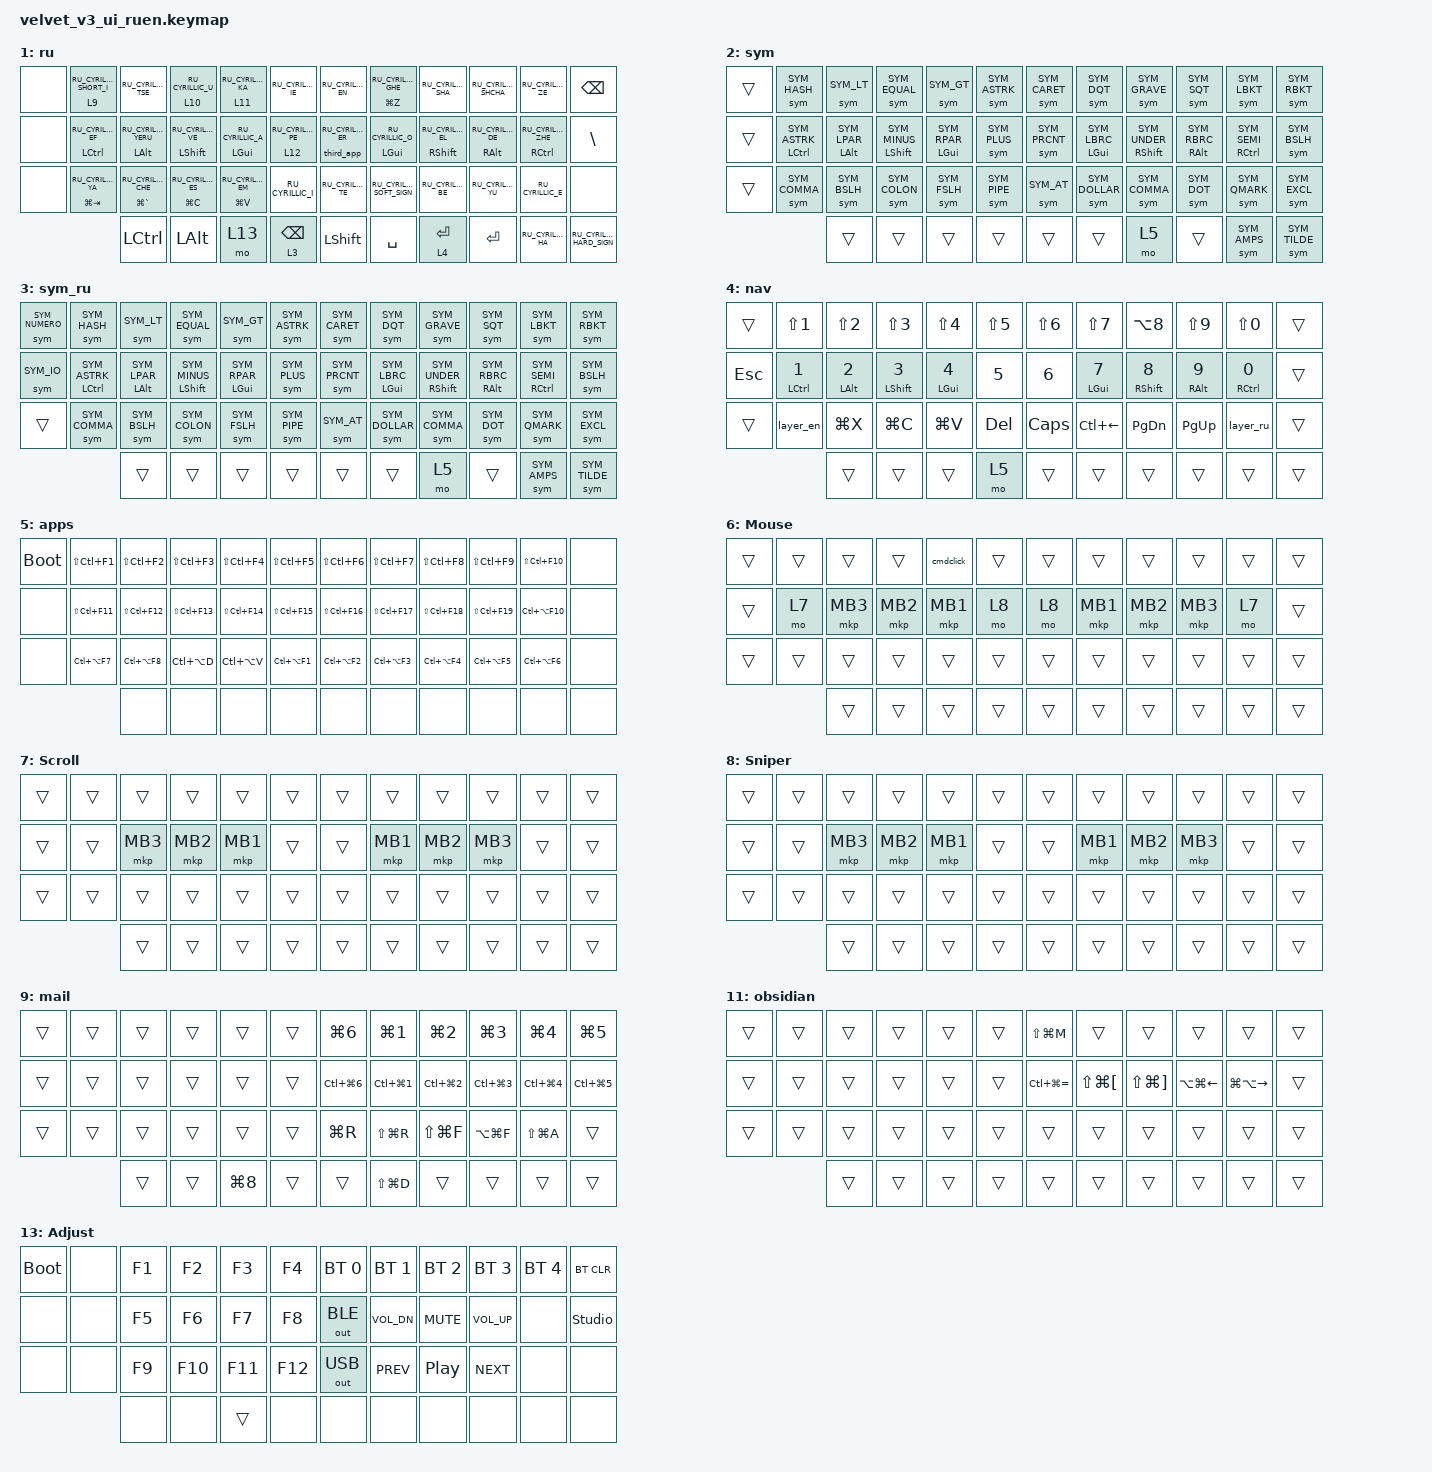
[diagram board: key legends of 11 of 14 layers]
#include "keys_ru.h"
#include "host_layout.dtsi"
#include "sym_glyph.h"
#include "sym_glyph.dtsi"
#include <dt-bindings/zmk/input_transform.h>
#include <input/processors.dtsi>
#include <zephyr/dt-bindings/input/input-event-codes.h>
#include <behaviors.dtsi>
#include <dt-bindings/zmk/bt.h>
#include <dt-bindings/zmk/keys.h>
#include <dt-bindings/zmk/outputs.h>
#include <dt-bindings/zmk/pointing.h>

&mt {
    quick-tap-ms = <175>;
    require-prior-idle-ms = <150>;
    flavor = "tap-preferred";
};

&lt {
    quick-tap-ms = <175>;
    require-prior-idle-ms = <150>;
    hold-while-undecided;
};

/ {
    behaviors {
        cap_sen: cap_sen {
            compatible = "zmk,behavior-hold-tap";
            label = "CAP_SEN";
            bindings = <&mo>, <&mkp>;

            #binding-cells = <2>;
            tapping-term-ms = <150>;
            hold-while-undecided;
        };

        mouse_layer: mouse_layer {
            compatible = "zmk,behavior-sticky-key";
            label = "MOUSE_LAYER";
            bindings = <&mo>;
            #binding-cells = <1>;
            release-after-ms = <200>;
        };

        /* Time-based home-row mods, same idea as toucan hrm_l / hrm_r:
         * the key becomes a modifier only after it has been held for
         * tapping-term-ms. quick-tap-ms matches that term, so a repeated
         * letter stays a tap.
         */
        hml: home_row_mod_left {
            compatible = "zmk,behavior-hold-tap";
            #binding-cells = <2>;
            bindings = <&kp>, <&kp>;
            flavor = "tap-preferred";
            tapping-term-ms = <300>;
            quick-tap-ms = <300>;
        };

        hmr: home_row_mod_right {
            compatible = "zmk,behavior-hold-tap";
            #binding-cells = <2>;
            bindings = <&kp>, <&kp>;
            flavor = "tap-preferred";
            tapping-term-ms = <300>;
            quick-tap-ms = <300>;
        };

        /* Symbol-layer home row: hold is still a modifier, tap is &sym. */
        hml_sym: home_row_mod_left_sym {
            compatible = "zmk,behavior-hold-tap";
            #binding-cells = <2>;
            bindings = <&kp>, <&sym>;
            flavor = "tap-preferred";
            tapping-term-ms = <300>;
            quick-tap-ms = <300>;
        };

        hmr_sym: home_row_mod_right_sym {
            compatible = "zmk,behavior-hold-tap";
            #binding-cells = <2>;
            bindings = <&kp>, <&sym>;
            flavor = "tap-preferred";
            tapping-term-ms = <300>;
            quick-tap-ms = <300>;
        };

        my_mt: my_mt {
            compatible = "zmk,behavior-hold-tap";
            bindings = <&kp>, <&kp>;

            #binding-cells = <2>;
            tapping-term-ms = <300>;
        };

        /* W+E combo: tap sends Tab, hold sends Enter. Same timing as toucan my_mt. */
        mt_tab: mt_tab {
            compatible = "zmk,behavior-hold-tap";
            #binding-cells = <2>;
            flavor = "tap-preferred";
            tapping-term-ms = <300>;
            bindings = <&kp>, <&kp>;
        };

        /* Hold H: Cmd+Tab+Tab, the third recent app. Tap still sends the letter. */
        h_third_app: h_third_app {
            compatible = "zmk,behavior-hold-tap";
            #binding-cells = <2>;
            flavor = "tap-preferred";
            tapping-term-ms = <300>;
            bindings = <&third_app>, <&kp>;
        };

        /* Hold: layer 12 (same as `&lt 12`). Tap: `&to` — same as layer_en (0) / layer_ru (1). */
        lt12_to: lt12_to {
            compatible = "zmk,behavior-hold-tap";
            #binding-cells = <2>;
            bindings = <&mo>, <&to>;
            tapping-term-ms = <200>;
            quick-tap-ms = <175>;
            require-prior-idle-ms = <150>;
            hold-while-undecided;
        };

        zip_auto_mouse: zip_auto_mouse {
            compatible = "zmk,input-processor-temp-layer";
            #input-processor-cells = <2>;
            require-prior-idle-ms = <800>;
            excluded-positions = <>;
        };

        /* E+R. Horizon: Alt+Shift for Windows. Otherwise toggle en/ru. */
        er_lang: er_lang {
            compatible = "zmk,behavior-er-lang";
            #binding-cells = <0>;
            display-name = "ER Lang";
        };
    };

    combos {
        compatible = "zmk,combos";

        er {
            bindings = <&er_lang>;
            key-positions = <3 4>;
            layers = <0 1>;
        };

        kha {
            bindings = <&kp RU_CYRILLIC_HA>;
            key-positions = <7 8>;
            layers = <1>;
        };

        hrd {
            bindings = <&kp RU_CYRILLIC_HARD_SIGN>;
            key-positions = <8 9>;
            layers = <1>;
        };

        caps_word {
            bindings = <&caps_word>;
            key-positions = <24 25>;
            layers = <0 1>;
        };

        combo_sd_esc {
            timeout-ms = <35>;
            require-prior-idle-ms = <125>;
            slow-release;
            key-positions = <14 15>;
            layers = <0 1>;
            bindings = <&kp ESC>;
        };

        combo_we_tab {
            timeout-ms = <35>;
            require-prior-idle-ms = <125>;
            slow-release;
            key-positions = <2 3>;
            layers = <0 1>;
            bindings = <&mt_tab RET TAB>;
        };
    };

    macros {
        to_ru: to_ru {
            compatible = "zmk,behavior-macro";
            #binding-cells = <0>;
            bindings = <&host_layout 1>;
            label = "TO_RU";
            wait-ms = <0>;
            tap-ms = <30>;
        };

        to_en: to_en {
            compatible = "zmk,behavior-macro";
            #binding-cells = <0>;
            bindings = <&host_layout 0>;
            label = "TO_EN";
            wait-ms = <0>;
            tap-ms = <30>;
        };

        layer_en: layer_en {
            compatible = "zmk,behavior-macro";
            #binding-cells = <0>;
            bindings = <&to 0>;
            label = "LAYER_EN";
            wait-ms = <0>;
            tap-ms = <30>;
        };

        layer_ru: layer_ru {
            compatible = "zmk,behavior-macro";
            #binding-cells = <0>;
            bindings = <&to 1>;
            label = "LAYER_RU";
            tap-ms = <30>;
            wait-ms = <0>;
        };

        en: en {
            compatible = "zmk,behavior-macro-one-param";
            #binding-cells = <1>;
            bindings =
                <&to_en>,
                <&macro_press>,
                <&macro_param_1to1 &host_key MACRO_PLACEHOLDER>,
                <&macro_pause_for_release>,
                <&macro_release>,
                <&macro_param_1to1 &host_key MACRO_PLACEHOLDER>,
                <&to_ru>;

            label = "EN";
            wait-ms = <0>;
            tap-ms = <30>;
        };

        ipad_ru: ipad_ru {
            compatible = "zmk,behavior-macro";
            #binding-cells = <0>;
            bindings = <&to 1 &kp CAPSLOCK>;
            label = "IPAD_RU";
        };

        ipad_en: ipad_en {
            compatible = "zmk,behavior-macro";
            #binding-cells = <0>;
            bindings = <&to 0 &kp CAPSLOCK>;
            label = "IPAD_EN";
        };

        cmdclick: cmdclick {
            compatible = "zmk,behavior-macro";
            #binding-cells = <0>;
            bindings =
                <&macro_press>,
                <&kp LEFT_GUI &mkp MB1>,
                <&macro_release>,
                <&mkp MB1 &kp LEFT_GUI>;

            label = "CMDCLICK";
        };

        en_1: en_1 {
            compatible = "zmk,behavior-macro-one-param";
            #binding-cells = <1>;
            bindings =
                <&to_en>,
                <&macro_press>,
                <&macro_param_1to1 &host_key MACRO_PLACEHOLDER>,
                <&macro_pause_for_release>,
                <&macro_release>,
                <&macro_param_1to1 &host_key MACRO_PLACEHOLDER>,
                <&to_ru>;

            label = "EN_1";
            wait-ms = <0>;
            tap-ms = <30>;
        };

        layer_en_old: layer_en_old {
            compatible = "zmk,behavior-macro";
            #binding-cells = <0>;
            bindings = <&to 0 &to_en>;
            label = "LAYER_EN_OLD";
            wait-ms = <0>;
            tap-ms = <30>;
        };

        layer_ru_old: layer_ru_old {
            compatible = "zmk,behavior-macro";
            #binding-cells = <0>;
            bindings = <&to 1 &to_ru>;
            label = "LAYER_RU_OLD";
            tap-ms = <30>;
            wait-ms = <0>;
        };

        third_app: third_app {
            compatible = "zmk,behavior-macro";
            #binding-cells = <0>;
            wait-ms = <40>;
            tap-ms = <40>;
            bindings =
                <&macro_press &kp LEFT_GUI>,
                <&macro_tap &kp TAB &kp TAB>,
                <&macro_release &kp LEFT_GUI>;
        };
    };

    keymap {
        compatible = "zmk,keymap";

        en {
            bindings = <
&none           &lt 9 Q              &kp W               &lt 10 E           &lt 11 R         &kp T                                     &kp Y  &my_mt LG(Z) U   &kp I               &kp O             &kp P                    &kp BSPC
&none           &hml LEFT_CONTROL A  &hml LEFT_ALT S     &hml LEFT_SHIFT D  &hml LEFT_GUI F  &lt 12 G                                   &h_third_app 0 H  &hmr LEFT_GUI J  &hmr RIGHT_SHIFT K  &hmr RIGHT_ALT L  &hmr RIGHT_CONTROL SEMI  &hmr BSLH LC(LA(LS(LEFT_GUI)))
&none           &my_mt LG(TAB) Z     &my_mt LG(GRAVE) X  &my_mt LG(C) C     &my_mt LG(V) V   &kp B                                     &kp N  &kp M            &kp COMMA           &kp DOT           &kp QUESTION             &none
                                     &kp LEFT_CONTROL    &kp LEFT_ALT       &mo 13           &lt 2 BACKSPACE  &kp LEFT_SHIFT  &kp SPACE  &lt 4 RETURN  &kp RETURN       &kp LBKT            &kp SLASH
            >;

            display-name = "base";
        };

        ru {
            display-name = "ru";
            bindings = <
&none           &lt 9 RU_CYRILLIC_SHORT_I         &kp RU_CYRILLIC_TSE               &lt 10 RU_CYRILLIC_U            &lt 11 RU_CYRILLIC_KA        &kp RU_CYRILLIC_IE                           &kp RU_CYRILLIC_EN  &my_mt LG(Z) RU_CYRILLIC_GHE  &kp RU_CYRILLIC_SHA              &kp RU_CYRILLIC_SHCHA          &kp RU_CYRILLIC_ZE                  &kp BSPC
&none           &hml LEFT_CONTROL RU_CYRILLIC_EF  &hml LEFT_ALT RU_CYRILLIC_YERU    &hml LEFT_SHIFT RU_CYRILLIC_VE  &hml LEFT_GUI RU_CYRILLIC_A  &lt 12 RU_CYRILLIC_PE                     &h_third_app 0 RU_CYRILLIC_ER  &hmr LEFT_GUI RU_CYRILLIC_O   &hmr RIGHT_SHIFT RU_CYRILLIC_EL  &hmr RIGHT_ALT RU_CYRILLIC_DE  &hmr RIGHT_CONTROL RU_CYRILLIC_ZHE  &kp BSLH
&none           &my_mt LG(TAB) RU_CYRILLIC_YA     &my_mt LG(GRAVE) RU_CYRILLIC_CHE  &my_mt LG(C) RU_CYRILLIC_ES     &my_mt LG(V) RU_CYRILLIC_EM  &kp RU_CYRILLIC_I                            &kp RU_CYRILLIC_TE  &kp RU_CYRILLIC_SOFT_SIGN     &kp RU_CYRILLIC_BE               &kp RU_CYRILLIC_YU             &kp RU_CYRILLIC_E                   &none
                                                  &kp LEFT_CONTROL                  &kp LEFT_ALT                    &mo 13                       &lt 3 BACKSPACE     &kp LEFT_SHIFT  &kp SPACE  &lt 4 RETURN          &kp RETURN                    &kp RU_CYRILLIC_HA               &kp RU_CYRILLIC_HARD_SIGN
            >;
        };

        /*
         * Same glyphs on Mac and in Horizon.
         * English base: one US scancode. Russian base: host unicode (0xB1).
         * Horizon focused (0xB0): Alt+numpad. № and ё are on sym_ru only.
         */
        sym {
            bindings = <
&trans  &sym SYM_HASH                    &sym SYM_LT              &sym SYM_EQUAL              &sym SYM_GT              &sym SYM_ASTRK                       &sym SYM_CARET  &sym SYM_DQT             &sym SYM_GRAVE               &sym SYM_SQT              &sym SYM_LBKT                 &sym SYM_RBKT
&trans  &hml_sym LEFT_CONTROL SYM_ASTRK  &hml_sym LEFT_ALT SYM_LPAR  &hml_sym LEFT_SHIFT SYM_MINUS  &hml_sym LEFT_GUI SYM_RPAR  &sym SYM_PLUS                     &sym SYM_PRCNT  &hmr_sym LEFT_GUI SYM_LBRC  &hmr_sym RIGHT_SHIFT SYM_UNDER  &hmr_sym RIGHT_ALT SYM_RBRC  &hmr_sym RIGHT_CONTROL SYM_SEMI  &sym SYM_BSLH
&trans  &sym SYM_COMMA                   &sym SYM_BSLH            &sym SYM_COLON              &sym SYM_FSLH            &sym SYM_PIPE                        &sym SYM_AT     &sym SYM_DOLLAR          &sym SYM_COMMA               &sym SYM_DOT              &sym SYM_QMARK                &sym SYM_EXCL
                                        &trans                   &trans                      &trans                   &trans        &trans    &trans  &mo 5      &trans                   &sym SYM_AMPS             &sym SYM_TILDE
            >;

            display-name = "sym";
        };

        sym_ru {
            display-name = "sym_ru";
            bindings = <
&sym SYM_NUMERO  &sym SYM_HASH                    &sym SYM_LT              &sym SYM_EQUAL              &sym SYM_GT              &sym SYM_ASTRK                       &sym SYM_CARET  &sym SYM_DQT             &sym SYM_GRAVE               &sym SYM_SQT              &sym SYM_LBKT                 &sym SYM_RBKT
&sym SYM_IO      &hml_sym LEFT_CONTROL SYM_ASTRK  &hml_sym LEFT_ALT SYM_LPAR  &hml_sym LEFT_SHIFT SYM_MINUS  &hml_sym LEFT_GUI SYM_RPAR  &sym SYM_PLUS                     &sym SYM_PRCNT  &hmr_sym LEFT_GUI SYM_LBRC  &hmr_sym RIGHT_SHIFT SYM_UNDER  &hmr_sym RIGHT_ALT SYM_RBRC  &hmr_sym RIGHT_CONTROL SYM_SEMI  &sym SYM_BSLH
&trans           &sym SYM_COMMA                   &sym SYM_BSLH            &sym SYM_COLON              &sym SYM_FSLH            &sym SYM_PIPE                        &sym SYM_AT     &sym SYM_DOLLAR          &sym SYM_COMMA               &sym SYM_DOT              &sym SYM_QMARK                &sym SYM_EXCL
                                                 &trans                   &trans                      &trans                   &trans        &trans    &trans  &mo 5      &trans                   &sym SYM_AMPS             &sym SYM_TILDE
            >;
        };

        digits {
            bindings = <
&trans      &kp LS(N1)                  &kp LS(N2)              &kp LS(N3)                &kp LS(N4)              &kp LS(N5)                      &kp LS(N6)  &kp LS(N7)        &kp LA(N8)                 &kp LS(N9)               &kp LS(N0)                   &trans
&kp ESCAPE  &hml LEFT_CONTROL NUMBER_1  &hml LEFT_ALT NUMBER_2  &hml LEFT_SHIFT NUMBER_3  &hml LEFT_GUI NUMBER_4  &kp NUMBER_5                    &kp N6      &hmr LEFT_GUI N7  &hmr RIGHT_SHIFT NUMBER_8  &hmr RIGHT_ALT NUMBER_9  &hmr RIGHT_CONTROL NUMBER_0  &trans
&trans      &layer_en                   &kp LG(X)               &kp LG(C)                 &kp LG(V)               &kp DEL                         &kp CLCK    &kp LC(LEFT)      &kp PAGE_DOWN              &kp PAGE_UP              &layer_ru                    &trans
                                        &trans                  &trans                    &trans                  &mo 5         &trans    &trans  &trans      &trans            &trans                     &trans
            >;

            display-name = "nav";
        };

        apps {
            /*
             * Apps layer → skhd (macOS).
             * Use only skhd-legal chords (f1–f20 / letters). F21+ make skhd abort
             * the whole skhdrc ("expected key-literal").
             * Z/X/V were LS(LC(F21/F22/F24)); remapped to LC(LA(F7/F8/V)).
             * ; = LC(LA(F10)) Horizon; C = LC(LA(D)); B.. = LC(LA(F1..F6))
             */
            bindings = <
&bootloader  &kp LS(LC(F1))   &kp LS(LC(F2))   &kp LS(LC(F3))   &kp LS(LC(F4))   &kp LS(LC(F5))                    &kp LS(LC(F6))   &kp LS(LC(F7))   &kp LS(LC(F8))   &kp LS(LC(F9))   &kp LS(LC(F10))  &none
&none        &kp LS(LC(F11))  &kp LS(LC(F12))  &kp LS(LC(F13))  &kp LS(LC(F14))  &kp LS(LC(F15))                   &kp LS(LC(F16))  &kp LS(LC(F17))  &kp LS(LC(F18))  &kp LS(LC(F19))  &kp LC(LA(F10))  &none
&none        &kp LC(LA(F7))   &kp LC(LA(F8))   &kp LC(LA(D))    &kp LC(LA(V))    &kp LC(LA(F1))                    &kp LC(LA(F2))   &kp LC(LA(F3))   &kp LC(LA(F4))   &kp LC(LA(F5))   &kp LC(LA(F6))   &none
                              &none            &none            &none            &none           &none    &none  &none            &none            &none            &none
            >;

            display-name = "apps";
        };

        mouse {
            bindings = <
&trans  &trans  &trans    &trans    &cmdclick  &trans                    &trans  &trans    &trans    &trans    &trans  &trans
&trans  &mo 7   &mkp MB3  &mkp MB2  &mkp MB1   &mo 8                     &mo 8   &mkp MB1  &mkp MB2  &mkp MB3  &mo 7   &trans
&trans  &trans  &trans    &trans    &trans     &trans                    &trans  &trans    &trans    &trans    &trans  &trans
                &trans    &trans    &trans     &trans  &trans    &trans  &trans  &trans    &trans    &trans
            >;

            display-name = "Mouse";
        };

        scroll {
            bindings = <
&trans  &trans  &trans    &trans    &trans    &trans                    &trans  &trans    &trans    &trans    &trans  &trans
&trans  &trans  &mkp MB3  &mkp MB2  &mkp MB1  &trans                    &trans  &mkp MB1  &mkp MB2  &mkp MB3  &trans  &trans
&trans  &trans  &trans    &trans    &trans    &trans                    &trans  &trans    &trans    &trans    &trans  &trans
                &trans    &trans    &trans    &trans  &trans    &trans  &trans  &trans    &trans    &trans
            >;

            display-name = "Scroll";
        };

        sniper {
            bindings = <
&trans  &trans  &trans    &trans    &trans    &trans                    &trans  &trans    &trans    &trans    &trans  &trans
&trans  &trans  &mkp MB3  &mkp MB2  &mkp MB1  &trans                    &trans  &mkp MB1  &mkp MB2  &mkp MB3  &trans  &trans
&trans  &trans  &trans    &trans    &trans    &trans                    &trans  &trans    &trans    &trans    &trans  &trans
                &trans    &trans    &trans    &trans  &trans    &trans  &trans  &trans    &trans    &trans
            >;

            display-name = "Sniper";
        };

        mail {
            bindings = <
&trans  &trans  &trans  &trans  &trans      &trans                           &kp LG(N6)      &kp LG(N1)      &kp LG(NUMBER_2)      &kp LG(NUMBER_3)      &kp LG(NUMBER_4)      &kp LG(N5)
&trans  &trans  &trans  &trans  &trans      &trans                           &kp LC(LG(N6))  &kp LC(LG(N1))  &kp LC(LG(NUMBER_2))  &kp LC(LG(NUMBER_3))  &kp LC(LG(NUMBER_4))  &kp LC(LG(NUMBER_5))
&trans  &trans  &trans  &trans  &trans      &trans                           &kp LG(R)       &kp LS(LG(R))   &kp LS(LG(F))         &kp LA(LG(F))         &kp LS(LG(A))         &trans
                &trans  &trans  &kp LG(N8)  &trans  &trans    &kp LS(LG(D))  &trans          &trans          &trans                &trans
            >;

            label = "mail";
        };

        things {
            bindings = <
&trans  &trans  &trans  &trans  &trans  &trans                           &kp LG(N1)         &kp LG(NUMBER_2)  &kp LG(NUMBER_4)  &kp LG(NUMBER_5)  &kp LS(LG(F))  &trans
&trans  &trans  &trans  &trans  &trans  &trans                           &kp LS(LG(P))      &kp LS(LG(M))     &kp LG(R)         &kp LG(O)         &kp LS(LG(D))  &trans
&trans  &trans  &trans  &trans  &trans  &trans                           &kp LG(LA(LC(N)))  &kp LS(LG(N))     &kp LS(LG(C))     &kp LS(LG(O))     &trans         &trans
                &trans  &trans  &trans  &trans  &trans    &kp LS(LG(T))  &trans             &trans            &trans            &trans
            >;

            label = "things";
        };

        obsidian {
            bindings = <
&trans  &trans  &trans  &trans  &trans  &trans                    &kp LS(LG(M))      &trans                    &trans            &trans                  &trans                   &trans
&trans  &trans  &trans  &trans  &trans  &trans                    &kp LC(LG(EQUAL))  &kp LS(LG(LEFT_BRACKET))  &kp LS(LG(RBKT))  &kp LA(LG(LEFT_ARROW))  &kp LG(LA(RIGHT_ARROW))  &trans
&trans  &trans  &trans  &trans  &trans  &trans                    &trans             &trans                    &trans            &trans                  &trans                   &trans
                &trans  &trans  &trans  &trans  &trans    &trans  &trans             &trans                    &trans            &trans
            >;

            label = "obsidian";
        };

        nav {
            display-name = "nav";
            bindings = <
&trans  &kp N1                    &kp LA(LC(LG(LS(W))))  &kp N3          &kp N4                              &kp N5                     &kp LS(LA(LEFT_ARROW))  &kp LS(LA(DOWN_ARROW))    &kp LS(LA(UP))             &kp LS(LA(RIGHT_ARROW))     &kp N0             &trans
&trans  &hml LEFT_CONTROL ESCAPE  &kp LEFT_ALT           &kp LEFT_SHIFT  &hml LEFT_GUI LG(LC(LS(NUMBER_4)))  &kp RET                    &kp LEFT_ARROW          &hmr LEFT_GUI DOWN_ARROW  &hmr RIGHT_SHIFT UP_ARROW  &hmr RIGHT_ALT RIGHT_ARROW  &kp RIGHT_CONTROL  &trans
&trans  &layer_en                 &kp LG(X)              &kp LG(C)       &kp LG(V)                           &kp DEL                    &kp LA(LEFT_ARROW)      &kp LA(DOWN_ARROW)        &kp LA(UP_ARROW)           &kp RA(RIGHT_ARROW)         &layer_ru          &trans
                                  &trans                 &trans          &trans                              &trans   &trans    &trans  &mo 5                   &trans                    &trans                     &trans
            >;
        };

        layer_13 {
            display-name = "Adjust";
            bindings = <
&bootloader  &none  &kp F1  &kp F2   &kp F3   &kp F4                   &bt BT_SEL 0  &bt BT_SEL 1  &bt BT_SEL 2      &bt BT_SEL 3  &bt BT_SEL 4  &bt BT_CLR
&none        &none  &kp F5  &kp F6   &kp F7   &kp F8                   &out OUT_BLE  &kp C_VOL_DN  &kp C_MUTE        &kp C_VOL_UP  &none         &studio_unlock
&none        &none  &kp F9  &kp F10  &kp F11  &kp F12                  &out OUT_USB  &kp C_PREV    &kp C_PLAY_PAUSE  &kp C_NEXT    &none         &none
                    &none   &none    &trans   &none    &none    &none  &none         &none         &none             &none
            >;
        };
    };
};

&trackball { cpi = <1000>; };

&trackball_listener {
    input-processors = <&zip_auto_mouse 6 500>, <&zip_xy_scaler 9 20>;

    scroller {
        layers = <7>;
        input-processors =
            <&zip_xy_transform INPUT_TRANSFORM_Y_INVERT>,
            <&zip_xy_scaler 1 32>,
            <&zip_xy_to_scroll_mapper>;
    };

    sniper {
        layers = <8>;
        input-processors = <&zip_xy_scaler 1 4>;
    };
};
